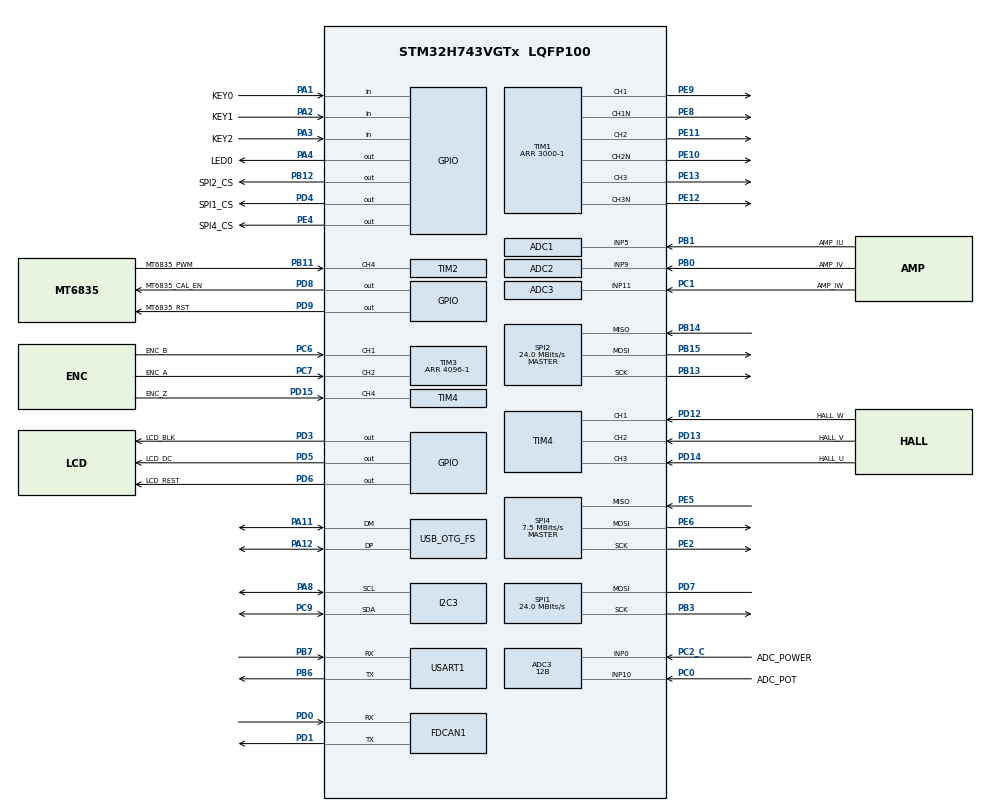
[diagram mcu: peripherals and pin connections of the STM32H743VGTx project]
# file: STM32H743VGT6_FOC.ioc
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ADC1.Channel-0\#ChannelRegularConversion=ADC_CHANNEL_5
ADC1.ClockPrescaler=ADC_CLOCK_SYNC_PCLK_DIV4
ADC1.ClockPrescalerADC3=ADC_CLOCK_SYNC_PCLK_DIV4
ADC1.EnableInjectedConversion=ENABLE
ADC1.ExternalTrigInjecConv=ADC_EXTERNALTRIGINJEC_T1_CC4
ADC1.InjNumberOfConversion=1
ADC1.InjectedChannel-1\#ChannelInjectedConversion=ADC_CHANNEL_5
ADC1.InjectedConvMode=Discontinuous
ADC1.InjectedOffsetNumber-1\#ChannelInjectedConversion=ADC_OFFSET_NONE
ADC1.InjectedOffsetSaturation-1\#ChannelInjectedConversion=DISABLE
ADC1.InjectedRank-1\#ChannelInjectedConversion=1
ADC1.InjectedSamplingTime-1\#ChannelInjectedConversion=ADC_SAMPLETIME_64CYCLES_5
ADC1.NbrOfConversionFlag=1
ADC1.OffsetNumber-0\#ChannelRegularConversion=ADC_OFFSET_NONE
ADC1.OffsetSignedSaturation-0\#ChannelRegularConversion=DISABLE
ADC1.Rank-0\#ChannelRegularConversion=1
ADC1.Resolution=ADC_RESOLUTION_12B
ADC1.SamplingTime-0\#ChannelRegularConversion=ADC_SAMPLETIME_1CYCLE_5
ADC1.master=1
ADC2.Channel-0\#ChannelRegularConversion=ADC_CHANNEL_9
ADC2.ClockPrescaler=ADC_CLOCK_SYNC_PCLK_DIV4
ADC2.ClockPrescalerADC3=ADC_CLOCK_SYNC_PCLK_DIV4
ADC2.EnableInjectedConversion=ENABLE
ADC2.ExternalTrigInjecConv=ADC_EXTERNALTRIGINJEC_T1_CC4
ADC2.InjNumberOfConversion=1
ADC2.InjectedChannel-1\#ChannelInjectedConversion=ADC_CHANNEL_9
ADC2.InjectedConvMode=Discontinuous
ADC2.InjectedOffsetNumber-1\#ChannelInjectedConversion=ADC_OFFSET_NONE
ADC2.InjectedOffsetSaturation-1\#ChannelInjectedConversion=DISABLE
ADC2.InjectedRank-1\#ChannelInjectedConversion=1
ADC2.InjectedSamplingTime-1\#ChannelInjectedConversion=ADC_SAMPLETIME_64CYCLES_5
ADC2.NbrOfConversionFlag=1
ADC2.OffsetNumber-0\#ChannelRegularConversion=ADC_OFFSET_NONE
ADC2.OffsetSignedSaturation-0\#ChannelRegularConversion=DISABLE
ADC2.Rank-0\#ChannelRegularConversion=1
ADC2.Resolution=ADC_RESOLUTION_12B
ADC2.SamplingTime-0\#ChannelRegularConversion=ADC_SAMPLETIME_1CYCLE_5
ADC3.Channel-0\#ChannelRegularConversion=ADC_CHANNEL_0
ADC3.Channel-1\#ChannelRegularConversion=ADC_CHANNEL_10
ADC3.ClockPrescalerADC3=ADC_CLOCK_SYNC_PCLK_DIV4
ADC3.ContinuousConvMode=ENABLE
ADC3.ConversionDataManagement=ADC_CONVERSIONDATA_DMA_ONESHOT
ADC3.EnableInjectedConversion=ENABLE
ADC3.ExternalTrigInjecConv=ADC_EXTERNALTRIGINJEC_T1_CC4
ADC3.InjNumberOfConversion=1
ADC3.InjectedChannel-2\#ChannelInjectedConversion=ADC_CHANNEL_11
ADC3.InjectedOffsetNumber-2\#ChannelInjectedConversion=ADC_OFFSET_NONE
ADC3.InjectedOffsetSaturation-2\#ChannelInjectedConversion=DISABLE
ADC3.InjectedRank-2\#ChannelInjectedConversion=1
ADC3.InjectedSamplingTime-2\#ChannelInjectedConversion=ADC_SAMPLETIME_64CYCLES_5
ADC3.NbrOfConversion=2
ADC3.NbrOfConversionFlag=1
ADC3.OffsetNumber-0\#ChannelRegularConversion=ADC_OFFSET_NONE
ADC3.OffsetNumber-1\#ChannelRegularConversion=ADC_OFFSET_NONE
ADC3.OffsetSignedSaturation-0\#ChannelRegularConversion=DISABLE
ADC3.Overrun=ADC_OVR_DATA_OVERWRITTEN
ADC3.Rank-0\#ChannelRegularConversion=1
ADC3.Rank-1\#ChannelRegularConversion=2
ADC3.Resolution=ADC_RESOLUTION_12B
ADC3.SamplingTime-0\#ChannelRegularConversion=ADC_SAMPLETIME_387CYCLES_5
ADC3.SamplingTime-1\#ChannelRegularConversion=ADC_SAMPLETIME_387CYCLES_5
CORTEX_M7.default_mode_Activation=1
Dma.ADC3.0.Direction=DMA_PERIPH_TO_MEMORY
Dma.ADC3.0.EventEnable=DISABLE
Dma.ADC3.0.FIFOMode=DMA_FIFOMODE_DISABLE
Dma.ADC3.0.Instance=DMA1_Stream0
Dma.ADC3.0.MemDataAlignment=DMA_MDATAALIGN_HALFWORD
Dma.ADC3.0.MemInc=DMA_MINC_ENABLE
Dma.ADC3.0.Mode=DMA_NORMAL
Dma.ADC3.0.PeriphDataAlignment=DMA_PDATAALIGN_HALFWORD
Dma.ADC3.0.PeriphInc=DMA_PINC_DISABLE
Dma.ADC3.0.Polarity=HAL_DMAMUX_REQ_GEN_RISING
Dma.ADC3.0.Priority=DMA_PRIORITY_LOW
Dma.ADC3.0.RequestNumber=1
Dma.ADC3.0.SignalID=NONE
Dma.ADC3.0.SyncEnable=DISABLE
Dma.ADC3.0.SyncPolarity=HAL_DMAMUX_SYNC_NO_EVENT
Dma.ADC3.0.SyncRequestNumber=1
Dma.ADC3.0.SyncSignalID=NONE
Dma.Request0=ADC3
FDCAN1.CalculateBaudRateNominal=250000
FDCAN1.CalculateTimeBitNominal=4000
FDCAN1.CalculateTimeQuantumNominal=200.0
FDCAN1.NominalPrescaler=20
FDCAN1.NominalSyncJumpWidth=3
FDCAN1.NominalTimeSeg1=16
FDCAN1.NominalTimeSeg2=3
I2C3.Timing=0x307075B1
Mcu.Family=STM32H7
Mcu.Name=STM32H743VGTx
Mcu.Package=LQFP100
NVIC.ADC3_IRQn=true\:1\:0\:true\:false\:true\:true\:true\:true
NVIC.ADC_IRQn=true\:1\:0\:true\:false\:true\:true\:true\:true
NVIC.DMA1_Stream0_IRQn=true\:5\:0\:true\:false\:true\:false\:true\:true
NVIC.FDCAN1_IT0_IRQn=true\:5\:0\:true\:false\:true\:true\:true\:true
NVIC.FDCAN1_IT1_IRQn=true\:5\:0\:true\:false\:true\:true\:true\:true
NVIC.OTG_FS_EP1_IN_IRQn=true\:15\:0\:true\:false\:true\:true\:true\:true
NVIC.OTG_FS_EP1_OUT_IRQn=true\:15\:0\:true\:false\:true\:true\:true\:true
NVIC.OTG_FS_IRQn=true\:15\:0\:true\:false\:true\:true\:true\:true
NVIC.PriorityGroup=NVIC_PRIORITYGROUP_4
NVIC.TIM1_UP_IRQn=true\:2\:0\:true\:false\:true\:true\:true\:true
NVIC.TIM4_IRQn=true\:3\:0\:true\:false\:true\:true\:true\:true
PA1.GPIO_Label=KEY0
PA1.GPIO_PuPd=GPIO_PULLUP
PA1.Signal=GPIO_Input
PA11.Mode=Device_Only
PA11.Signal=USB_OTG_FS_DM
PA12.Mode=Device_Only
PA12.Signal=USB_OTG_FS_DP
PA13\ (JTMS/SWDIO).Mode=Serial_Wire
PA13\ (JTMS/SWDIO).Signal=DEBUG_JTMS-SWDIO
PA14\ (JTCK/SWCLK).Mode=Serial_Wire
PA14\ (JTCK/SWCLK).Signal=DEBUG_JTCK-SWCLK
PA2.GPIO_Label=KEY1
PA2.GPIO_PuPd=GPIO_PULLUP
PA2.Signal=GPIO_Input
PA3.GPIO_Label=KEY2
PA3.GPIO_PuPd=GPIO_PULLUP
PA3.Signal=GPIO_Input
PA4.GPIO_Label=LED0
PA4.GPIO_ModeDefaultOutputPP=GPIO_MODE_OUTPUT_PP
PA4.GPIO_PuPd=GPIO_PULLDOWN
PA4.Signal=GPIO_Output
PA8.Mode=I2C
PA8.Signal=I2C3_SCL
PB0.GPIO_Label=AMP_IV
PB0.Signal=ADCx_INP9
PB1.GPIO_Label=AMP_IU
PB1.Signal=ADCx_INP5
PB11.GPIO_Label=MT6835_PWM
PB11.Signal=S_TIM2_CH4
PB12.GPIO_Label=SPI2_CS
PB12.Signal=GPIO_Output
PB13.Mode=Full_Duplex_Master
PB13.Signal=SPI2_SCK
PB14.Mode=Full_Duplex_Master
PB14.Signal=SPI2_MISO
PB15.Mode=Full_Duplex_Master
PB15.Signal=SPI2_MOSI
PB3\ (JTDO/TRACESWO).Mode=Simplex_Bidirectional_Master
PB3\ (JTDO/TRACESWO).Signal=SPI1_SCK
PB6.Mode=Asynchronous
PB6.Signal=USART1_TX
PB7.Mode=Asynchronous
PB7.Signal=USART1_RX
PC0.GPIO_Label=ADC_POT
PC0.Signal=ADCx_INP10
PC1.GPIO_Label=AMP_IW
PC1.Signal=ADCx_INP11
PC2_C.GPIO_Label=ADC_POWER
PC2_C.Mode=IN0-Single-Ended
PC2_C.Signal=ADC3_INP0
PC6.GPIO_Label=ENC_B
PC6.Signal=S_TIM3_CH1
PC7.GPIO_Label=ENC_A
PC7.Signal=S_TIM3_CH2
PC9.Mode=I2C
PC9.Signal=I2C3_SDA
PD0.Mode=FDCAN_Activate
PD0.Signal=FDCAN1_RX
PD1.Mode=FDCAN_Activate
PD1.Signal=FDCAN1_TX
PD12.GPIO_Label=HALL_W
PD12.Signal=S_TIM4_CH1
PD13.GPIO_Label=HALL_V
PD13.Signal=S_TIM4_CH2
PD14.GPIO_Label=HALL_U
PD14.Signal=S_TIM4_CH3
PD15.GPIO_Label=ENC_Z
PD15.Signal=S_TIM4_CH4
PD3.GPIO_Label=LCD_BLK
PD3.GPIO_PuPd=GPIO_PULLUP
PD3.Signal=GPIO_Output
PD4.GPIO_Label=SPI1_CS
PD4.GPIO_PuPd=GPIO_PULLUP
PD4.GPIO_Speed=GPIO_SPEED_FREQ_VERY_HIGH
PD4.Signal=GPIO_Output
PD5.GPIO_Label=LCD_DC
PD5.GPIO_PuPd=GPIO_PULLUP
PD5.Signal=GPIO_Output
PD6.GPIO_Label=LCD_REST
PD6.GPIO_PuPd=GPIO_PULLUP
PD6.Signal=GPIO_Output
PD7.Mode=Simplex_Bidirectional_Master
PD7.Signal=SPI1_MOSI
PD8.GPIO_Label=MT6835_CAL_EN
PD8.GPIO_PuPd=GPIO_PULLUP
PD8.Signal=GPIO_Output
PD9.GPIO_Label=MT6835_RST
PD9.GPIO_PuPd=GPIO_PULLUP
PD9.Signal=GPIO_Output
PE10.Mode=PWM Generation2 CH2 CH2N
PE10.Signal=TIM1_CH2N
PE11.Signal=S_TIM1_CH2
PE12.Mode=PWM Generation3 CH3 CH3N
PE12.Signal=TIM1_CH3N
PE13.Signal=S_TIM1_CH3
PE2.Mode=Full_Duplex_Master
PE2.Signal=SPI4_SCK
PE4.GPIO_Label=SPI4_CS
PE4.Signal=GPIO_Output
PE5.Mode=Full_Duplex_Master
PE5.Signal=SPI4_MISO
PE6.Mode=Full_Duplex_Master
PE6.Signal=SPI4_MOSI
PE8.Mode=PWM Generation1 CH1 CH1N
PE8.Signal=TIM1_CH1N
PE9.Signal=S_TIM1_CH1
PH0-OSC_IN\ (PH0).Mode=HSE-External-Oscillator
PH0-OSC_IN\ (PH0).Signal=RCC_OSC_IN
PH1-OSC_OUT\ (PH1).Mode=HSE-External-Oscillator
PH1-OSC_OUT\ (PH1).Signal=RCC_OSC_OUT
ProjectManager.HeapSize=0x7000
ProjectManager.StackSize=0x1000
ProjectManager.TargetToolchain=MDK-ARM V5
RCC.ADCFreq_Value=100000000
RCC.APB1Freq_Value=120000000
RCC.APB2Freq_Value=120000000
RCC.APB3Freq_Value=120000000
RCC.APB4Freq_Value=120000000
RCC.CortexFreq_Value=480000000
RCC.D1PPRE=RCC_APB3_DIV2
RCC.D2PPRE1=RCC_APB1_DIV2
RCC.D2PPRE2=RCC_APB2_DIV2
RCC.D3PPRE=RCC_APB4_DIV2
RCC.DIVM1=5
RCC.DIVM2=5
RCC.DIVN1=192
RCC.DIVN2=40
RCC.DIVQ1=10
RCC.FDCANCLockSelection=RCC_FDCANCLKSOURCE_PLL2
RCC.HCLKFreq_Value=240000000
RCC.HPRE=RCC_HCLK_DIV2
RCC.PLLSourceVirtual=RCC_PLLSOURCE_HSE
RCC.SYSCLKFreq_VALUE=480000000
RCC.SYSCLKSource=RCC_SYSCLKSOURCE_PLLCLK
RCC.USBCLockSelection=RCC_USBCLKSOURCE_HSI48
RCC.USBFreq_Value=48000000
SH.ADCx_INP10.0=ADC3_INP10,IN10-Single-Ended
SH.ADCx_INP11.0=ADC3_INP11,IN11-Single-Ended
SH.ADCx_INP5.0=ADC1_INP5,IN5-Single-Ended
SH.ADCx_INP9.0=ADC2_INP9,IN9-Single-Ended
SH.S_TIM1_CH1.0=TIM1_CH1,PWM Generation1 CH1 CH1N
SH.S_TIM1_CH2.0=TIM1_CH2,PWM Generation2 CH2 CH2N
SH.S_TIM1_CH3.0=TIM1_CH3,PWM Generation3 CH3 CH3N
SH.S_TIM2_CH4.0=TIM2_CH4,Input_Capture4_from_TI4
SH.S_TIM3_CH1.0=TIM3_CH1,Encoder_Interface
SH.S_TIM3_CH2.0=TIM3_CH2,Encoder_Interface
SH.S_TIM4_CH1.0=TIM4_CH1,Xored_Inputs_Hall_Sensor_Interface
SH.S_TIM4_CH2.0=TIM4_CH2,Xored_Inputs_Hall_Sensor_Interface
SH.S_TIM4_CH3.0=TIM4_CH3,Xored_Inputs_Hall_Sensor_Interface
SH.S_TIM4_CH4.0=TIM4_CH4,Input_Capture4_from_TI4
SPI1.BaudRatePrescaler=SPI_BAUDRATEPRESCALER_4
SPI1.CalculateBaudRate=24.0 MBits/s
SPI1.Direction=SPI_DIRECTION_1LINE
SPI1.Mode=SPI_MODE_MASTER
SPI1.VirtualType=VM_MASTER
SPI2.BaudRatePrescaler=SPI_BAUDRATEPRESCALER_4
SPI2.CLKPhase=SPI_PHASE_2EDGE
SPI2.CLKPolarity=SPI_POLARITY_HIGH
SPI2.CalculateBaudRate=24.0 MBits/s
SPI2.DataSize=SPI_DATASIZE_8BIT
SPI2.Direction=SPI_DIRECTION_2LINES
SPI2.Mode=SPI_MODE_MASTER
SPI2.VirtualType=VM_MASTER
SPI4.BaudRatePrescaler=SPI_BAUDRATEPRESCALER_16
SPI4.CLKPhase=SPI_PHASE_2EDGE
SPI4.CLKPolarity=SPI_POLARITY_HIGH
SPI4.CalculateBaudRate=7.5 MBits/s
SPI4.DataSize=SPI_DATASIZE_8BIT
SPI4.Direction=SPI_DIRECTION_2LINES
SPI4.Mode=SPI_MODE_MASTER
SPI4.VirtualType=VM_MASTER
TIM1.Channel-PWM\ Generation1\ CH1\ CH1N=TIM_CHANNEL_1
TIM1.Channel-PWM\ Generation2\ CH2\ CH2N=TIM_CHANNEL_2
TIM1.Channel-PWM\ Generation3\ CH3\ CH3N=TIM_CHANNEL_3
TIM1.Channel-PWM\ Generation4\ No\ Output=TIM_CHANNEL_4
TIM1.CounterMode=TIM_COUNTERMODE_CENTERALIGNED1
TIM1.OCMode_PWM-PWM\ Generation1\ CH1\ CH1N=TIM_OCMODE_PWM2
TIM1.OCMode_PWM-PWM\ Generation2\ CH2\ CH2N=TIM_OCMODE_PWM2
TIM1.OCMode_PWM-PWM\ Generation3\ CH3\ CH3N=TIM_OCMODE_PWM2
TIM1.OCMode_PWM-PWM\ Generation4\ No\ Output=TIM_OCMODE_PWM2
TIM1.Period=3000-1
TIM1.Pulse-PWM\ Generation4\ No\ Output=10
TIM1.TIM_MasterOutputTrigger=TIM_TRGO_OC4REF
TIM2.Channel-Input_Capture4_from_TI4=TIM_CHANNEL_4
TIM3.EncoderMode=TIM_ENCODERMODE_TI12
TIM3.IC1Filter=15
TIM3.IC2Filter=15
TIM3.Period=4096-1
TIM4.Channel-Input_Capture4_from_TI4=TIM_CHANNEL_4
USART1.VirtualMode-Asynchronous=VM_ASYNC
USB_OTG_FS.VirtualMode=Device_Only
VP_TIM1_VS_no_output4.Mode=PWM Generation4 No Output
VP_TIM7_VS_ClockSourceINT.Mode=Enable_Timer
VP_VREFBUF_V_VREFBUF.Mode=ExternalMode
board=custom

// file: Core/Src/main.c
/* USER CODE BEGIN Header */
/**
  ******************************************************************************
  * @file           : main.c
  * @brief          : Main program body
  ******************************************************************************
  * @attention
  *
  * Copyright (c) 2026 STMicroelectronics.
  * All rights reserved.
  *
  * This software is licensed under terms that can be found in the LICENSE file
  * in the root directory of this software component.
  * If no LICENSE file comes with this software, it is provided AS-IS.
  *
  ******************************************************************************
  */
/* USER CODE END Header */
#include "main.h"
#include "adc.h"
#include "dma.h"
#include "fdcan.h"
#include "i2c.h"
#include "spi.h"
#include "tim.h"
#include "usart.h"
#include "usb_otg.h"
#include "gpio.h"

/* USER CODE BEGIN Includes */
#include <sys_m7.h>
#include <debug.h>
void BSP_Init(void);
/* USER CODE END Includes */

void SystemClock_Config(void);
void PeriphCommonClock_Config(void);
static void MPU_Config(void);

int main(void)
{

  /* MPU Configuration--------------------------------------------------------*/
  MPU_Config();

  /* MCU Configuration--------------------------------------------------------*/

  /* Reset of all peripherals, Initializes the Flash interface and the Systick. */
  HAL_Init();

  /* Configure the system clock */
  SystemClock_Config();

/* Configure the peripherals common clocks */
  PeriphCommonClock_Config();

  /* Initialize all configured peripherals */
  MX_GPIO_Init();
  MX_DMA_Init();
  MX_ADC2_Init();
  MX_ADC1_Init();
  MX_ADC3_Init();
  MX_FDCAN1_Init();
  MX_I2C3_Init();
  MX_SPI1_Init();
  MX_SPI2_Init();
  MX_SPI4_Init();
  MX_TIM1_Init();
  MX_TIM2_Init();
  MX_TIM3_Init();
  MX_TIM4_Init();
  MX_TIM7_Init();
  MX_USART1_UART_Init();
  MX_USB_OTG_FS_PCD_Init();
  /* USER CODE BEGIN 2 */
    BSP_Init();
  /* USER CODE END 2 */

  /* Infinite loop */
  while (1)
  {

    /* USER CODE BEGIN 3 */
        // HAL_GPIO_TogglePin(LED0_GPIO_Port, LED0_Pin);
        // HAL_Delay(500);
        Debug_Task();

  }
  /* USER CODE END 3 */
}

void SystemClock_Config(void)
{
  RCC_OscInitTypeDef RCC_OscInitStruct = {0};
  RCC_ClkInitTypeDef RCC_ClkInitStruct = {0};

  /** Supply configuration update enable
  */
  HAL_PWREx_ConfigSupply(PWR_LDO_SUPPLY);

  /** Configure the main internal regulator output voltage
  */
  __HAL_PWR_VOLTAGESCALING_CONFIG(PWR_REGULATOR_VOLTAGE_SCALE1);

  while(!__HAL_PWR_GET_FLAG(PWR_FLAG_VOSRDY)) {}

  __HAL_RCC_SYSCFG_CLK_ENABLE();
  __HAL_PWR_VOLTAGESCALING_CONFIG(PWR_REGULATOR_VOLTAGE_SCALE0);

  while(!__HAL_PWR_GET_FLAG(PWR_FLAG_VOSRDY)) {}

  /** Initializes the RCC Oscillators according to the specified parameters
  * in the RCC_OscInitTypeDef structure.
  */
  RCC_OscInitStruct.OscillatorType = RCC_OSCILLATORTYPE_HSI48|RCC_OSCILLATORTYPE_HSE;
  RCC_OscInitStruct.HSEState = RCC_HSE_ON;
  RCC_OscInitStruct.HSI48State = RCC_HSI48_ON;
  RCC_OscInitStruct.PLL.PLLState = RCC_PLL_ON;
  RCC_OscInitStruct.PLL.PLLSource = RCC_PLLSOURCE_HSE;
  RCC_OscInitStruct.PLL.PLLM = 5;
  RCC_OscInitStruct.PLL.PLLN = 192;
  RCC_OscInitStruct.PLL.PLLP = 2;
  RCC_OscInitStruct.PLL.PLLQ = 10;
  RCC_OscInitStruct.PLL.PLLR = 2;
  RCC_OscInitStruct.PLL.PLLRGE = RCC_PLL1VCIRANGE_2;
  RCC_OscInitStruct.PLL.PLLVCOSEL = RCC_PLL1VCOWIDE;
  RCC_OscInitStruct.PLL.PLLFRACN = 0;
  if (HAL_RCC_OscConfig(&RCC_OscInitStruct) != HAL_OK)
  {
    Error_Handler();
  }

  /** Initializes the CPU, AHB and APB buses clocks
  */
  RCC_ClkInitStruct.ClockType = RCC_CLOCKTYPE_HCLK|RCC_CLOCKTYPE_SYSCLK
                              |RCC_CLOCKTYPE_PCLK1|RCC_CLOCKTYPE_PCLK2
                              |RCC_CLOCKTYPE_D3PCLK1|RCC_CLOCKTYPE_D1PCLK1;
  RCC_ClkInitStruct.SYSCLKSource = RCC_SYSCLKSOURCE_PLLCLK;
  RCC_ClkInitStruct.SYSCLKDivider = RCC_SYSCLK_DIV1;
  RCC_ClkInitStruct.AHBCLKDivider = RCC_HCLK_DIV2;
  RCC_ClkInitStruct.APB3CLKDivider = RCC_APB3_DIV2;
  RCC_ClkInitStruct.APB1CLKDivider = RCC_APB1_DIV2;
  RCC_ClkInitStruct.APB2CLKDivider = RCC_APB2_DIV2;
  RCC_ClkInitStruct.APB4CLKDivider = RCC_APB4_DIV2;

  if (HAL_RCC_ClockConfig(&RCC_ClkInitStruct, FLASH_LATENCY_4) != HAL_OK)
  {
    Error_Handler();
  }
}

void PeriphCommonClock_Config(void)
{
  RCC_PeriphCLKInitTypeDef PeriphClkInitStruct = {0};

  /** Initializes the peripherals clock
  */
  PeriphClkInitStruct.PeriphClockSelection = RCC_PERIPHCLK_ADC|RCC_PERIPHCLK_FDCAN;
  PeriphClkInitStruct.PLL2.PLL2M = 5;
  PeriphClkInitStruct.PLL2.PLL2N = 40;
  PeriphClkInitStruct.PLL2.PLL2P = 2;
  PeriphClkInitStruct.PLL2.PLL2Q = 2;
  PeriphClkInitStruct.PLL2.PLL2R = 2;
  PeriphClkInitStruct.PLL2.PLL2RGE = RCC_PLL2VCIRANGE_2;
  PeriphClkInitStruct.PLL2.PLL2VCOSEL = RCC_PLL2VCOWIDE;
  PeriphClkInitStruct.PLL2.PLL2FRACN = 0;
  PeriphClkInitStruct.FdcanClockSelection = RCC_FDCANCLKSOURCE_PLL2;
  PeriphClkInitStruct.AdcClockSelection = RCC_ADCCLKSOURCE_PLL2;
  if (HAL_RCCEx_PeriphCLKConfig(&PeriphClkInitStruct) != HAL_OK)
  {
    Error_Handler();
  }
}

 /* MPU Configuration */

void MPU_Config(void)
{
  MPU_Region_InitTypeDef MPU_InitStruct = {0};

  /* Disables the MPU */
  HAL_MPU_Disable();

  /** Initializes and configures the Region and the memory to be protected
  */
  MPU_InitStruct.Enable = MPU_REGION_ENABLE;
  MPU_InitStruct.Number = MPU_REGION_NUMBER0;
  MPU_InitStruct.BaseAddress = 0x0;
  MPU_InitStruct.Size = MPU_REGION_SIZE_4GB;
  MPU_InitStruct.SubRegionDisable = 0x87;
  MPU_InitStruct.TypeExtField = MPU_TEX_LEVEL0;
  MPU_InitStruct.AccessPermission = MPU_REGION_NO_ACCESS;
  MPU_InitStruct.DisableExec = MPU_INSTRUCTION_ACCESS_DISABLE;
  MPU_InitStruct.IsShareable = MPU_ACCESS_SHAREABLE;
  MPU_InitStruct.IsCacheable = MPU_ACCESS_NOT_CACHEABLE;
  MPU_InitStruct.IsBufferable = MPU_ACCESS_NOT_BUFFERABLE;

  HAL_MPU_ConfigRegion(&MPU_InitStruct);
  /* Enables the MPU */
  HAL_MPU_Enable(MPU_PRIVILEGED_DEFAULT);

}

void Error_Handler(void)
{
  __disable_irq();
  while (1)
  {
  }
}
